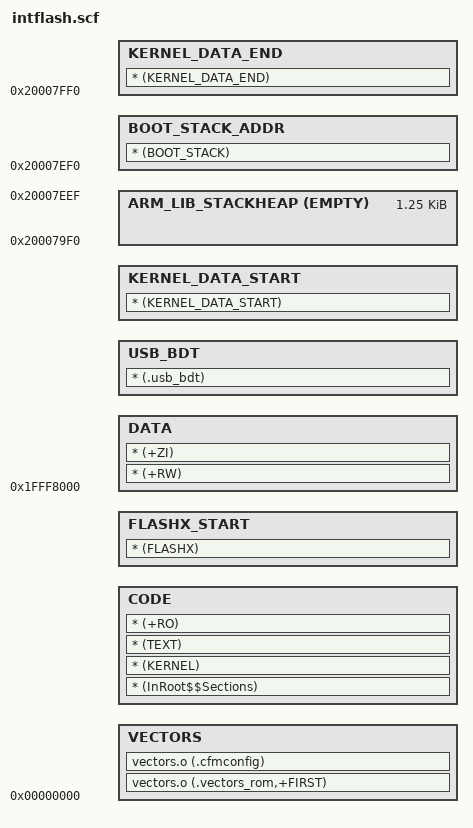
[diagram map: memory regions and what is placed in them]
#! armcc -E

#define FLASHX_SECT_SIZE        0x800
#define USERFLASH_BASE_ADDR     0x00030000
#define INTFLASH_BASE_ADDR      0x00000000
#define INTFLASH_SIZE           (USERFLASH_BASE_ADDR - INTFLASH_BASE_ADDR)

#define MY_ALIGN(address, alignment) ((address + (alignment-1)) AND ~(alignment-1))

LOAD_REGION_INTFLASH INTFLASH_BASE_ADDR INTFLASH_SIZE
{
    VECTORS INTFLASH_BASE_ADDR
    {
        vectors.o (.vectors_rom,+FIRST)
        vectors.o (.cfmconfig)
    }

    CODE +0
    {
        * (InRoot$$Sections)      ; All library sections for example, __main.o,
                                  ; __scatter*.o, __dc*.o, and * Region$$Table
        * (KERNEL)
        * (TEXT)
        * (+RO)
    }
 
    ; make sure this alignment matches the alignment in kernel_data.s in the bsp
    FLASHX_START MY_ALIGN(ImageLimit(CODE), FLASHX_SECT_SIZE)
    {
        * (FLASHX)
    }

    DATA 0x1FFF8000
    {
        * (+RW)
        * (+ZI)
    }

    USB_BDT MY_ALIGN(ImageLimit(DATA), 512)
    {
        * (.usb_bdt)
    }

    KERNEL_DATA_START MY_ALIGN(ImageLimit(USB_BDT), 0x10)
    {
        * (KERNEL_DATA_START)     ; start of kernel data
    }
    
    KERNEL_DATA_END 0x20007FF0      ; RAM_END
    {
        * (KERNEL_DATA_END)     ; end of kernel data
    }

    ; mem_init writes a storeblock_struct at the end of kernel data, 
    ; max size 32 bytes, so use 0x100 offset
    BOOT_STACK_ADDR 0x20007EF0 
    {
        * (BOOT_STACK)
    }

    ARM_LIB_STACKHEAP 0x200079F0 EMPTY 0x500
    {
    }
}
